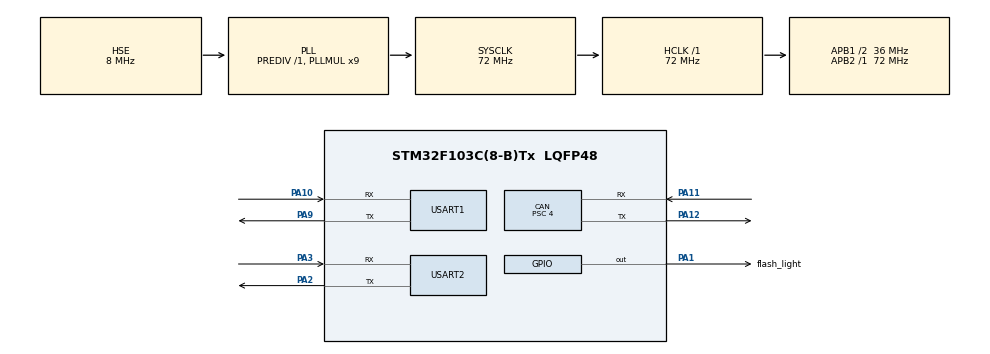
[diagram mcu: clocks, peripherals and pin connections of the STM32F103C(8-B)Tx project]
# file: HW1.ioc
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CAN.BS1=CAN_BS1_3TQ
CAN.BS2=CAN_BS2_5TQ
CAN.CalculateBaudRate=1000000
CAN.CalculateTimeBit=1000
CAN.CalculateTimeQuantum=111.11111111111111
CAN.Mode=CAN_MODE_LOOPBACK
CAN.Prescaler=4
Dma.Request0=USART1_TX
Dma.Request1=USART2_RX
Dma.USART1_TX.0.Direction=DMA_MEMORY_TO_PERIPH
Dma.USART1_TX.0.Instance=DMA1_Channel4
Dma.USART1_TX.0.MemDataAlignment=DMA_MDATAALIGN_BYTE
Dma.USART1_TX.0.MemInc=DMA_MINC_ENABLE
Dma.USART1_TX.0.Mode=DMA_NORMAL
Dma.USART1_TX.0.PeriphDataAlignment=DMA_PDATAALIGN_BYTE
Dma.USART1_TX.0.PeriphInc=DMA_PINC_DISABLE
Dma.USART1_TX.0.Priority=DMA_PRIORITY_MEDIUM
Dma.USART2_RX.1.Direction=DMA_PERIPH_TO_MEMORY
Dma.USART2_RX.1.Instance=DMA1_Channel6
Dma.USART2_RX.1.MemDataAlignment=DMA_MDATAALIGN_BYTE
Dma.USART2_RX.1.MemInc=DMA_MINC_ENABLE
Dma.USART2_RX.1.Mode=DMA_NORMAL
Dma.USART2_RX.1.PeriphDataAlignment=DMA_PDATAALIGN_BYTE
Dma.USART2_RX.1.PeriphInc=DMA_PINC_DISABLE
Dma.USART2_RX.1.Priority=DMA_PRIORITY_MEDIUM
Mcu.Family=STM32F1
Mcu.Name=STM32F103C(8-B)Tx
Mcu.Package=LQFP48
NVIC.DMA1_Channel4_IRQn=true\:5\:0\:true\:false\:true\:false\:true\:true
NVIC.DMA1_Channel6_IRQn=true\:4\:0\:true\:false\:true\:false\:true\:true
NVIC.PriorityGroup=NVIC_PRIORITYGROUP_4
NVIC.TIM3_IRQn=true\:0\:0\:false\:false\:true\:true\:true\:true
NVIC.USART1_IRQn=true\:3\:0\:true\:false\:true\:true\:true\:true
NVIC.USART2_IRQn=true\:1\:0\:true\:false\:true\:true\:true\:true
NVIC.USB_LP_CAN1_RX0_IRQn=true\:2\:0\:true\:false\:true\:true\:true\:true
PA1.GPIO_Label=flash_light
PA1.GPIO_Speed=GPIO_SPEED_FREQ_HIGH
PA1.PinState=GPIO_PIN_SET
PA1.Signal=GPIO_Output
PA10.Mode=Asynchronous
PA10.Signal=USART1_RX
PA11.Mode=CAN_Activate
PA11.Signal=CAN_RX
PA12.Mode=CAN_Activate
PA12.Signal=CAN_TX
PA13.Mode=Serial_Wire
PA13.Signal=SYS_JTMS-SWDIO
PA14.Mode=Serial_Wire
PA14.Signal=SYS_JTCK-SWCLK
PA2.Mode=Asynchronous
PA2.Signal=USART2_TX
PA3.Mode=Asynchronous
PA3.Signal=USART2_RX
PA9.Mode=Asynchronous
PA9.Signal=USART1_TX
PD0-OSC_IN.Mode=HSE-External-Oscillator
PD0-OSC_IN.Signal=RCC_OSC_IN
PD1-OSC_OUT.Mode=HSE-External-Oscillator
PD1-OSC_OUT.Signal=RCC_OSC_OUT
ProjectManager.HeapSize=0x200
ProjectManager.StackSize=0x400
ProjectManager.TargetToolchain=CMake
RCC.AHBFreq_Value=72000000
RCC.APB1CLKDivider=RCC_HCLK_DIV2
RCC.APB1Freq_Value=36000000
RCC.APB1TimFreq_Value=72000000
RCC.APB2Freq_Value=72000000
RCC.APB2TimFreq_Value=72000000
RCC.HCLKFreq_Value=72000000
RCC.PLLMUL=RCC_PLL_MUL9
RCC.PLLSourceVirtual=RCC_PLLSOURCE_HSE
RCC.SYSCLKFreq_VALUE=72000000
RCC.SYSCLKSource=RCC_SYSCLKSOURCE_PLLCLK
RCC.USBFreq_Value=72000000
TIM3.Period=1000-1
TIM3.Prescaler=72-1
USART1.VirtualMode=VM_ASYNC
USART2.VirtualMode=VM_ASYNC
VP_TIM3_VS_ClockSourceINT.Mode=Internal
board=custom

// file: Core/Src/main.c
/* USER CODE BEGIN Header */
/**
  ******************************************************************************
  * @file           : main.c
  * @brief          : Main program body
  ******************************************************************************
  * @attention
  *
  * Copyright (c) 2024 STMicroelectronics.
  * All rights reserved.
  *
  * This software is licensed under terms that can be found in the LICENSE file
  * in the root directory of this software component.
  * If no LICENSE file comes with this software, it is provided AS-IS.
  *
  ******************************************************************************
  */
/* USER CODE END Header */
#include "main.h"
#include "can.h"
#include "dma.h"
#include "tim.h"
#include "usart.h"
#include "gpio.h"

/* USER CODE BEGIN Includes */
#include "main_task.h"
/* USER CODE END Includes */

void SystemClock_Config(void);

int main(void)
{

  /* MCU Configuration--------------------------------------------------------*/

  /* Reset of all peripherals, Initializes the Flash interface and the Systick. */
  HAL_Init();

  /* Configure the system clock */
  SystemClock_Config();

  /* Initialize all configured peripherals */
  MX_GPIO_Init();
  MX_DMA_Init();
  MX_CAN_Init();
  MX_TIM3_Init();
  MX_USART1_UART_Init();
  MX_USART2_UART_Init();
  /* USER CODE BEGIN 2 */
  RobotInit();
      MainInit();

  /* USER CODE END 2 */

  /* Infinite loop */
  while (1)
  {

  }
}

void SystemClock_Config(void)
{
  RCC_OscInitTypeDef RCC_OscInitStruct = {0};
  RCC_ClkInitTypeDef RCC_ClkInitStruct = {0};

  /** Initializes the RCC Oscillators according to the specified parameters
  * in the RCC_OscInitTypeDef structure.
  */
  RCC_OscInitStruct.OscillatorType = RCC_OSCILLATORTYPE_HSE;
  RCC_OscInitStruct.HSEState = RCC_HSE_ON;
  RCC_OscInitStruct.HSEPredivValue = RCC_HSE_PREDIV_DIV1;
  RCC_OscInitStruct.HSIState = RCC_HSI_ON;
  RCC_OscInitStruct.PLL.PLLState = RCC_PLL_ON;
  RCC_OscInitStruct.PLL.PLLSource = RCC_PLLSOURCE_HSE;
  RCC_OscInitStruct.PLL.PLLMUL = RCC_PLL_MUL9;
  if (HAL_RCC_OscConfig(&RCC_OscInitStruct) != HAL_OK)
  {
    Error_Handler();
  }

  /** Initializes the CPU, AHB and APB buses clocks
  */
  RCC_ClkInitStruct.ClockType = RCC_CLOCKTYPE_HCLK|RCC_CLOCKTYPE_SYSCLK
                              |RCC_CLOCKTYPE_PCLK1|RCC_CLOCKTYPE_PCLK2;
  RCC_ClkInitStruct.SYSCLKSource = RCC_SYSCLKSOURCE_PLLCLK;
  RCC_ClkInitStruct.AHBCLKDivider = RCC_SYSCLK_DIV1;
  RCC_ClkInitStruct.APB1CLKDivider = RCC_HCLK_DIV2;
  RCC_ClkInitStruct.APB2CLKDivider = RCC_HCLK_DIV1;

  if (HAL_RCC_ClockConfig(&RCC_ClkInitStruct, FLASH_LATENCY_2) != HAL_OK)
  {
    Error_Handler();
  }
}

void Error_Handler(void)
{
  __disable_irq();
  while (1)
  {
  }
}
